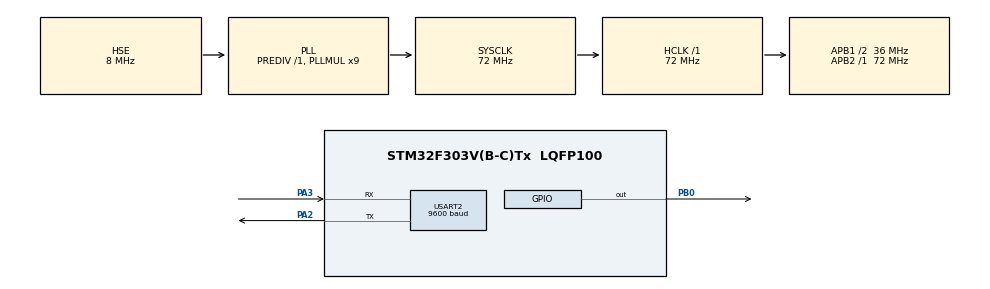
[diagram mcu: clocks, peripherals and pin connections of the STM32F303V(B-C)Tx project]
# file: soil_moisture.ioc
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Mcu.Family=STM32F3
Mcu.Name=STM32F303V(B-C)Tx
Mcu.Package=LQFP100
NVIC.PriorityGroup=NVIC_PRIORITYGROUP_4
NVIC.USART2_IRQn=true\:0\:0\:false\:false\:true\:true\:true\:true
PA13.Mode=Serial_Wire
PA13.Signal=SYS_JTMS-SWDIO
PA14.Mode=Serial_Wire
PA14.Signal=SYS_JTCK-SWCLK
PA2.Mode=Asynchronous
PA2.Signal=USART2_TX
PA3.Mode=Asynchronous
PA3.Signal=USART2_RX
PB0.Signal=GPIO_Output
PF0-OSC_IN.Mode=HSE-External-Oscillator
PF0-OSC_IN.Signal=RCC_OSC_IN
PF1-OSC_OUT.Mode=HSE-External-Oscillator
PF1-OSC_OUT.Signal=RCC_OSC_OUT
ProjectManager.HeapSize=0x200
ProjectManager.StackSize=0x400
ProjectManager.TargetToolchain=STM32CubeIDE
RCC.AHBFreq_Value=72000000
RCC.APB1CLKDivider=RCC_HCLK_DIV2
RCC.APB1Freq_Value=36000000
RCC.APB1TimFreq_Value=72000000
RCC.APB2Freq_Value=72000000
RCC.APB2TimFreq_Value=72000000
RCC.CortexFreq_Value=72000000
RCC.HCLKFreq_Value=72000000
RCC.HSE_VALUE=8000000
RCC.HSI_VALUE=8000000
RCC.LSE_VALUE=32768
RCC.PLLMUL=RCC_PLL_MUL9
RCC.PLLSourceVirtual=RCC_PLLSOURCE_HSE
RCC.SYSCLKFreq_VALUE=72000000
RCC.SYSCLKSourceVirtual=RCC_SYSCLKSOURCE_PLLCLK
RCC.USBFreq_Value=72000000
USART2.BaudRate=9600
USART2.VirtualMode-Asynchronous=VM_ASYNC
board=custom

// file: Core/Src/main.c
/* USER CODE BEGIN Header */
/**
  ******************************************************************************
  * @file           : main.c
  * @brief          : Main program body
  ******************************************************************************
  * @attention
  *
  * Copyright (c) 2025 STMicroelectronics.
  * All rights reserved.
  *
  * This software is licensed under terms that can be found in the LICENSE file
  * in the root directory of this software component.
  * If no LICENSE file comes with this software, it is provided AS-IS.
  *
  ******************************************************************************
  */
/* USER CODE END Header */
#include "main.h"

/* USER CODE BEGIN PTD */
#define RS485_UART      &huart2
#define RS485_DE_PIN    GPIO_PIN_0
#define RS485_DE_PORT   GPIOB
uint8_t modbus_request[] = {0x01, 0x03, 0x00, 0x00, 0x00, 0x02, 0xC4, 0x0B}; // Read 3 registers from address 0x00
uint8_t response[9];  // Response frame from sensor
/* USER CODE END PTD */

UART_HandleTypeDef huart2;

void SystemClock_Config(void);
static void MX_GPIO_Init(void);
static void MX_USART2_UART_Init(void);

/* USER CODE BEGIN 0 */
// Function to control RS485 transmit/receive
void RS485_SetMode(uint8_t mode) {
    if (mode) {
        HAL_GPIO_WritePin(RS485_DE_PORT, RS485_DE_PIN, GPIO_PIN_SET); // Transmit Mode
    } else {
        HAL_GPIO_WritePin(RS485_DE_PORT, RS485_DE_PIN, GPIO_PIN_RESET); // Receive Mode
    }
}

// Function to send Modbus request and receive response
void RS485_ReadSensor() {
    RS485_SetMode(1);  // Enable Transmit Mode
    HAL_UART_Transmit(RS485_UART, modbus_request, sizeof(modbus_request), HAL_MAX_DELAY);
    HAL_Delay(10);  // Wait for transmission to complete

    RS485_SetMode(0);  // Enable Receive Mode
    HAL_UART_Receive(RS485_UART, response, 9, 100);  // Receive sensor response
}

// Function to process sensor data
void ProcessSensorData() {
    if (response[0] == 0x01 && response[1] == 0x03) {  // Valid Modbus response
        uint16_t temp_raw = (response[3] << 8) | response[4];
        uint16_t hum_raw  = (response[5] << 8) | response[6];
        uint16_t ec_raw   = (response[7] << 8) | response[8];

        float temperature = temp_raw / 10.0;  // Convert to Celsius
        float humidity    = hum_raw / 10.0;   // Convert to %
        float ec          = ec_raw;           // EC in µS/cm

    } else {
        printf("Invalid response\n");
    }
}
/* USER CODE END 0 */

int main(void)
{

  /* MCU Configuration--------------------------------------------------------*/

  /* Reset of all peripherals, Initializes the Flash interface and the Systick. */
  HAL_Init();

  /* Configure the system clock */
  SystemClock_Config();

  /* Initialize all configured peripherals */
  MX_GPIO_Init();
  MX_USART2_UART_Init();

  /* Infinite loop */
  while (1)
  {

    /* USER CODE BEGIN 3 */
      RS485_ReadSensor();
      ProcessSensorData();
      HAL_Delay(2000);  // Read every 2 seconds
  }
  /* USER CODE END 3 */
}

void SystemClock_Config(void)
{
  RCC_OscInitTypeDef RCC_OscInitStruct = {0};
  RCC_ClkInitTypeDef RCC_ClkInitStruct = {0};
  RCC_PeriphCLKInitTypeDef PeriphClkInit = {0};

  /** Initializes the RCC Oscillators according to the specified parameters
  * in the RCC_OscInitTypeDef structure.
  */
  RCC_OscInitStruct.OscillatorType = RCC_OSCILLATORTYPE_HSE;
  RCC_OscInitStruct.HSEState = RCC_HSE_ON;
  RCC_OscInitStruct.HSEPredivValue = RCC_HSE_PREDIV_DIV1;
  RCC_OscInitStruct.HSIState = RCC_HSI_ON;
  RCC_OscInitStruct.PLL.PLLState = RCC_PLL_ON;
  RCC_OscInitStruct.PLL.PLLSource = RCC_PLLSOURCE_HSE;
  RCC_OscInitStruct.PLL.PLLMUL = RCC_PLL_MUL9;
  if (HAL_RCC_OscConfig(&RCC_OscInitStruct) != HAL_OK)
  {
    Error_Handler();
  }

  /** Initializes the CPU, AHB and APB buses clocks
  */
  RCC_ClkInitStruct.ClockType = RCC_CLOCKTYPE_HCLK|RCC_CLOCKTYPE_SYSCLK
                              |RCC_CLOCKTYPE_PCLK1|RCC_CLOCKTYPE_PCLK2;
  RCC_ClkInitStruct.SYSCLKSource = RCC_SYSCLKSOURCE_PLLCLK;
  RCC_ClkInitStruct.AHBCLKDivider = RCC_SYSCLK_DIV1;
  RCC_ClkInitStruct.APB1CLKDivider = RCC_HCLK_DIV2;
  RCC_ClkInitStruct.APB2CLKDivider = RCC_HCLK_DIV1;

  if (HAL_RCC_ClockConfig(&RCC_ClkInitStruct, FLASH_LATENCY_2) != HAL_OK)
  {
    Error_Handler();
  }
  PeriphClkInit.PeriphClockSelection = RCC_PERIPHCLK_USART2;
  PeriphClkInit.Usart2ClockSelection = RCC_USART2CLKSOURCE_PCLK1;
  if (HAL_RCCEx_PeriphCLKConfig(&PeriphClkInit) != HAL_OK)
  {
    Error_Handler();
  }
}

static void MX_USART2_UART_Init(void)
{

  huart2.Instance = USART2;
  huart2.Init.BaudRate = 9600;
  huart2.Init.WordLength = UART_WORDLENGTH_8B;
  huart2.Init.StopBits = UART_STOPBITS_1;
  huart2.Init.Parity = UART_PARITY_NONE;
  huart2.Init.Mode = UART_MODE_TX_RX;
  huart2.Init.HwFlowCtl = UART_HWCONTROL_NONE;
  huart2.Init.OverSampling = UART_OVERSAMPLING_16;
  huart2.Init.OneBitSampling = UART_ONE_BIT_SAMPLE_DISABLE;
  huart2.AdvancedInit.AdvFeatureInit = UART_ADVFEATURE_NO_INIT;
  if (HAL_UART_Init(&huart2) != HAL_OK)
  {
    Error_Handler();
  }

}

static void MX_GPIO_Init(void)
{
  GPIO_InitTypeDef GPIO_InitStruct = {0};

  /* GPIO Ports Clock Enable */
  __HAL_RCC_GPIOF_CLK_ENABLE();
  __HAL_RCC_GPIOA_CLK_ENABLE();
  __HAL_RCC_GPIOB_CLK_ENABLE();

  /*Configure GPIO pin Output Level */
  HAL_GPIO_WritePin(GPIOB, GPIO_PIN_0, GPIO_PIN_RESET);

  /*Configure GPIO pin : PB0 */
  GPIO_InitStruct.Pin = GPIO_PIN_0;
  GPIO_InitStruct.Mode = GPIO_MODE_OUTPUT_PP;
  GPIO_InitStruct.Pull = GPIO_NOPULL;
  GPIO_InitStruct.Speed = GPIO_SPEED_FREQ_LOW;
  HAL_GPIO_Init(GPIOB, &GPIO_InitStruct);

}

void Error_Handler(void)
{
  __disable_irq();
  while (1)
  {
  }
}
